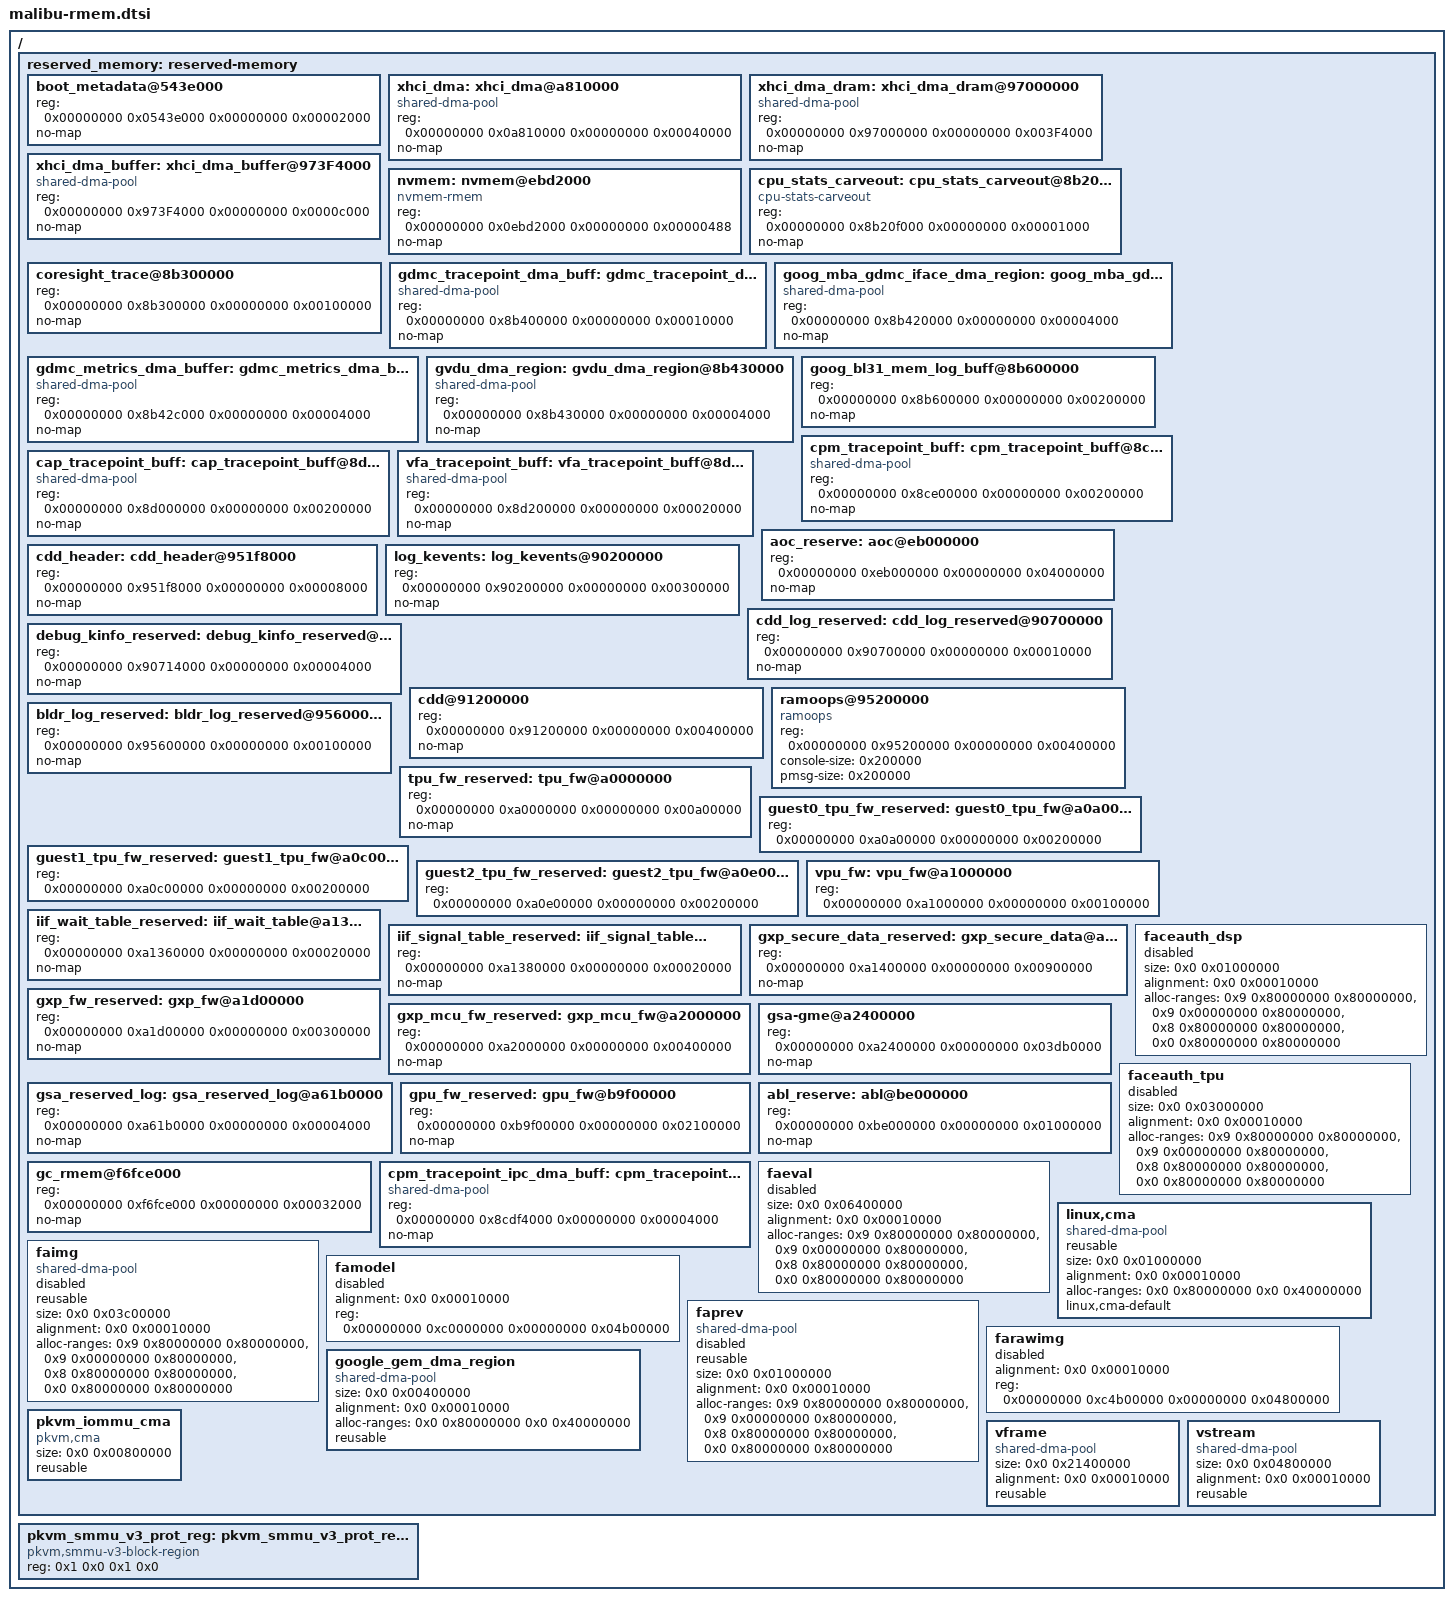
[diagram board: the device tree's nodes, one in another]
// SPDX-License-Identifier: GPL-2.0 OR BSD-3-Clause
#include <dt-bindings/soc/google/google-cdd-def.h>

/ {
	reserved_memory: reserved-memory {
		#address-cells = <0x00000002>;
		#size-cells = <0x00000002>;
		ranges;

		boot_metadata@543e000 {
			reg = <0x00000000 0x0543e000 0x00000000 0x00002000>; /* 8KB */
			no-map;
		};

		xhci_dma: xhci_dma@a810000 {
			compatible = "shared-dma-pool";
			reg = <0x00000000 0x0a810000 0x00000000 0x00040000>; /* 256KB */
			no-map;
		};

		xhci_dma_dram: xhci_dma_dram@97000000 {
			compatible = "shared-dma-pool";
			reg = <0x00000000 0x97000000 0x00000000 0x003F4000>; /* 4048KB */
			no-map;
		};

		xhci_dma_buffer: xhci_dma_buffer@973F4000 {
			compatible = "shared-dma-pool";
			reg = <0x00000000 0x973F4000 0x00000000 0x0000c000>; /* 48KB */
			no-map;
		};

		/* CPM OTP Shadow Registers */
		nvmem: nvmem@ebd2000 {
			compatible = "nvmem-rmem";
			reg = <0x00000000 0x0ebd2000 0x00000000 0x00000488>; /* 1160B */
			no-map;
		};

		cpu_stats_carveout: cpu_stats_carveout@8b20f000 {
			compatible = "cpu-stats-carveout";
			reg = <0x00000000 0x8b20f000 0x00000000 0x00001000>; /* 4KB */
			no-map;
		};

		/* CoreSight trace buffer carveout */
		coresight_trace@8b300000 {
			reg = <0x00000000 0x8b300000 0x00000000 0x00100000>; /* 1MB */
			no-map;
		};

		/* DMA buffer for the AP to receive GDMC tracepoints */
		gdmc_tracepoint_dma_buff: gdmc_tracepoint_dma_buff@8b400000 {
			compatible = "shared-dma-pool";
			reg = <0x00000000 0x8b400000 0x00000000 0x00010000>; /* 64KB */
			no-map;
		};

		/* DMA region for the AP to receive dump from AOC reset */
		goog_mba_gdmc_iface_dma_region: goog_mba_gdmc_iface_dma_region@8b420000 {
			compatible = "shared-dma-pool";
			reg = <0x00000000 0x8b420000 0x00000000 0x00004000>; /* 16KB */
			no-map;
		};

		/* DMA buffer for the GDMC FWMT mailbox  */
		gdmc_metrics_dma_buffer: gdmc_metrics_dma_buffer@8b42c000 {
			compatible = "shared-dma-pool";
			reg = <0x00000000 0x8b42c000 0x00000000 0x00004000>; /* 16KB */
			no-map;
		};

		/* DMA region for the GVDU mailbox buffer */
		gvdu_dma_region: gvdu_dma_region@8b430000 {
			compatible = "shared-dma-pool";
			reg = <0x00000000 0x8b430000 0x00000000 0x00004000>; /* 16KB */
			no-map;
		};

		/* TF-A mem log buffer */
		goog_bl31_mem_log_buff@8b600000 {
			reg = <0x00000000 0x8b600000 0x00000000 0x00200000>; /* 2MB */
			no-map;
		};

		/* CPM DRAM tracepoint buffer */
		cpm_tracepoint_buff: cpm_tracepoint_buff@8ce00000 {
			compatible = "shared-dma-pool";
			reg = <0x00000000 0x8ce00000 0x00000000 0x00200000>; /* 2MB */
			no-map;
		};

		/* CAP DRAM tracepoint buffer */
		cap_tracepoint_buff: cap_tracepoint_buff@8d000000 {
			compatible = "shared-dma-pool";
			reg = <0x00000000 0x8d000000 0x00000000 0x00200000>; /* 2MB */
			no-map;
		};

		/* VFA DRAM tracepoint buffer */
		vfa_tracepoint_buff: vfa_tracepoint_buff@8d200000 {
			compatible = "shared-dma-pool";
			reg = <0x00000000 0x8d200000 0x00000000 0x00020000>; /* 128KB */
			no-map;
		};

		aoc_reserve: aoc@eb000000 {
			reg = <0x00000000 0xeb000000 0x00000000 0x04000000>; /* 64MB */
			no-map;
		};

		/* begin crash_debug_dump rmem section */
		cdd_header: cdd_header@951f8000 {
			reg = <0x00000000 0x951f8000 0x00000000 0x00008000>; /* 32KB */
			no-map;
		};

		log_kevents: log_kevents@90200000 {
			reg = <0x00000000 0x90200000 0x00000000 0x00300000>; /* 3MB */
			no-map;
		};
		/* end crash_debug_dump rmem section */

		cdd_log_reserved: cdd_log_reserved@90700000 {
			reg = <0x00000000 0x90700000 0x00000000 0x00010000>; /* 64KB */
			no-map;
		};

		debug_kinfo_reserved: debug_kinfo_reserved@90714000 {
			reg = <0x00000000 0x90714000 0x00000000 0x00004000>; /* 16KB */
			no-map;
		};

		cdd@91200000 {
			reg = <0x00000000 0x91200000 0x00000000 0x00400000>; /* 4MB */
			no-map;
		};

		/*
		 * Store ramoops at a known location in DRAM, for access by the ABL
		 * following a crash-reset.
		 */
		ramoops@95200000 {
			compatible = "ramoops";
			reg = <0x00000000 0x95200000 0x00000000 0x00400000>; /* 4MB */
			console-size = <0x200000>;
			pmsg-size = <0x200000>;
		};

		bldr_log_reserved: bldr_log_reserved@95600000 {
			reg = <0x00000000 0x95600000 0x00000000 0x00100000>; /* 1MB */
			no-map;
		};

		/* TPU firmware and client data */
		tpu_fw_reserved: tpu_fw@a0000000 {
			reg = <0x00000000 0xa0000000 0x00000000 0x00a00000>; /* 10MB */
			no-map;
		};

		guest0_tpu_fw_reserved: guest0_tpu_fw@a0a00000 {
			reg = <0x00000000 0xa0a00000 0x00000000 0x00200000>; /* 2MB */
			/* Carveouts cannot be donated if marked with no-map. */
		};

		guest1_tpu_fw_reserved: guest1_tpu_fw@a0c00000 {
			reg = <0x00000000 0xa0c00000 0x00000000 0x00200000>; /* 2MB */
			/* Carveouts cannot be donated if marked with no-map. */
		};

		guest2_tpu_fw_reserved: guest2_tpu_fw@a0e00000 {
			reg = <0x00000000 0xa0e00000 0x00000000 0x00200000>; /* 2MB */
			/* Carveouts cannot be donated if marked with no-map. */
		};

		vpu_fw: vpu_fw@a1000000 {
			reg = <0x00000000 0xa1000000 0x00000000 0x00100000>; /* 1MB */
		};

		iif_wait_table_reserved: iif_wait_table@a1360000 {
			reg = <0x00000000 0xa1360000 0x00000000 0x00020000>; /* 128KB */
			no-map;
		};

		iif_signal_table_reserved: iif_signal_table@a1380000 {
			reg = <0x00000000 0xa1380000 0x00000000 0x00020000>; /* 128KB */
			no-map;
		};

		gxp_secure_data_reserved: gxp_secure_data@a1400000 {
			reg = <0x00000000 0xa1400000 0x00000000 0x00900000>; /* 9MB */
			no-map;
		};

		gxp_fw_reserved: gxp_fw@a1d00000 {
			reg = <0x00000000 0xa1d00000 0x00000000 0x00300000>; /* 3MB */
			no-map;
		};

		gxp_mcu_fw_reserved: gxp_mcu_fw@a2000000 {
			reg = <0x00000000 0xa2000000 0x00000000 0x00400000>; /* 4MB */
			no-map;
		};

		/* 63172KB maps to 48MB of GME + cipher metadata */
		gsa-gme@a2400000 {
			reg = <0x00000000 0xa2400000 0x00000000 0x03db0000>; /* 63168KB */
			no-map;
		};

		gsa_reserved_log: gsa_reserved_log@a61b0000 {
			reg = <0x00000000 0xa61b0000 0x00000000 0x00004000>; /* 16KB */
			no-map;
		};

		/* GPU firmware */
		gpu_fw_reserved: gpu_fw@b9f00000 {
			reg = <0x00000000 0xb9f00000 0x00000000 0x02100000>; /* 33MB */
			no-map;
		};

		abl_reserve: abl@be000000 {
			reg = <0x00000000 0xbe000000 0x00000000 0x01000000>; /* 16MB */
			no-map;
		};

		/* Global Config binary */
		gc_rmem@f6fce000 {
			reg = <0x00000000 0xf6fce000 0x00000000 0x00032000>; /* 200 KiB */
			no-map;
		};

		cpm_tracepoint_ipc_dma_buff: cpm_tracepoint_ipc_dma_buff@8cdf4000 {
			compatible = "shared-dma-pool";
			reg = <0x00000000 0x8cdf4000 0x00000000 0x00004000>; /* 16KB */
			no-map;
		};

		faceauth_dsp: faceauth_dsp {
			size = <0x0 0x01000000>; /* 16MB */
			alignment = <0x0 0x00010000>;
			alloc-ranges = <0x9 0x80000000 0x80000000>,
				<0x9 0x00000000 0x80000000>,
				<0x8 0x80000000 0x80000000>,
				<0x0 0x80000000 0x80000000>;
			status = "disabled";
		};

		faceauth_tpu: faceauth_tpu {
			size = <0x0 0x03000000>; /* 48MB */
			alignment = <0x0 0x00010000>;
			alloc-ranges = <0x9 0x80000000 0x80000000>,
				<0x9 0x00000000 0x80000000>,
				<0x8 0x80000000 0x80000000>,
				<0x0 0x80000000 0x80000000>;
			status = "disabled";
		};

		faeval: faeval {
			size = <0x0 0x06400000>; /* 100MB */
			alignment = <0x0 0x00010000>;
			alloc-ranges = <0x9 0x80000000 0x80000000>,
				<0x9 0x00000000 0x80000000>,
				<0x8 0x80000000 0x80000000>,
				<0x0 0x80000000 0x80000000>;
			status = "disabled";
		};

		linux,cma {
			compatible = "shared-dma-pool";
			reusable;
			size = <0x0 0x01000000>; /* 16MB */
			alignment = <0x0 0x00010000>;
			alloc-ranges = <0x0 0x80000000 0x0 0x40000000>;
			linux,cma-default;
		};

		faimg: faimg {
			compatible = "shared-dma-pool";
			reusable;
			size = <0x0 0x03c00000>; /* 60MB */
			alignment = <0x0 0x00010000>;
			alloc-ranges = <0x9 0x80000000 0x80000000>,
				<0x9 0x00000000 0x80000000>,
				<0x8 0x80000000 0x80000000>,
				<0x0 0x80000000 0x80000000>;
			status = "disabled";
		};

		famodel: famodel {
			alignment = <0x0 0x00010000>;
			/* 75MB: Overlaps S2M 61MB */
			reg = <0x00000000 0xc0000000 0x00000000 0x04b00000>;
			status = "disabled";
		};

		faprev: faprev {
			compatible = "shared-dma-pool";
			reusable;
			size = <0x0 0x01000000>; /* 16MB */
			alignment = <0x0 0x00010000>;
			alloc-ranges = <0x9 0x80000000 0x80000000>,
				<0x9 0x00000000 0x80000000>,
				<0x8 0x80000000 0x80000000>,
				<0x0 0x80000000 0x80000000>;
			status = "disabled";
		};

		farawimg: farawimg {
			alignment = <0x0 0x00010000>;
			/* 72MB: Overlaps ABL FB 20MB */
			reg = <0x00000000 0xc4b00000 0x00000000 0x04800000>;
			status = "disabled";
		};

		google_gem_dma_region: google_gem_dma_region {
			compatible = "shared-dma-pool";
			size = <0x0 0x00400000>; /* 4MB */
			alignment = <0x0 0x00010000>;
			alloc-ranges = <0x0 0x80000000 0x0 0x40000000>;
			reusable;
		};

#ifndef CONFIG_ARM64_16K_PAGES
		pkvm_iommu_cma: pkvm_iommu_cma {
			compatible = "pkvm,cma", "shared-dma-pool";
			size = <0x0 0x00800000>; /* 8MB */
			reusable;
		};
#endif

		vframe: vframe {
			compatible = "shared-dma-pool";
			size = <0x0 0x21400000>; /* 532MB */
			alignment = <0x0 0x00010000>;
			reusable;
		};

		vstream: vstream {
			compatible = "shared-dma-pool";
			size = <0x0 0x04800000>; /* 72MB */
			alignment = <0x0 0x00010000>;
			reusable;
		};
	};

	/*
	 * The physical address range from 4GB to 8GB is unassigned, and
	 * transactions targeting this range will fail. To simplify the
	 * debugging of such errors, we catch them at IOMMU level by marking
	 * this range as invalid in the stage-2 translation table.
	 */
	pkvm_smmu_v3_prot_reg: pkvm_smmu_v3_prot_reg@100000000 {
	       compatible = "pkvm,smmu-v3-block-region";
	       reg = <0x1 0x0 0x1 0x0>;
	};
};
